# CFGAP register map
Vendor: Texas Instruments
Peripheral module from a debugger description file (folder AP).
Registers are 32-bit, read-only, reset 0x0 unless marked. A register's access mark holds for its fields unless they carry their own. Offsets are as the file gives them; lines under a group give offsets from that group; [hi:lo] are bit positions; {n}, {i} and the like mark numbered series; 'fields as' and 'values as' point back to an identical list; <NAME> marks a mode.

## Hidden
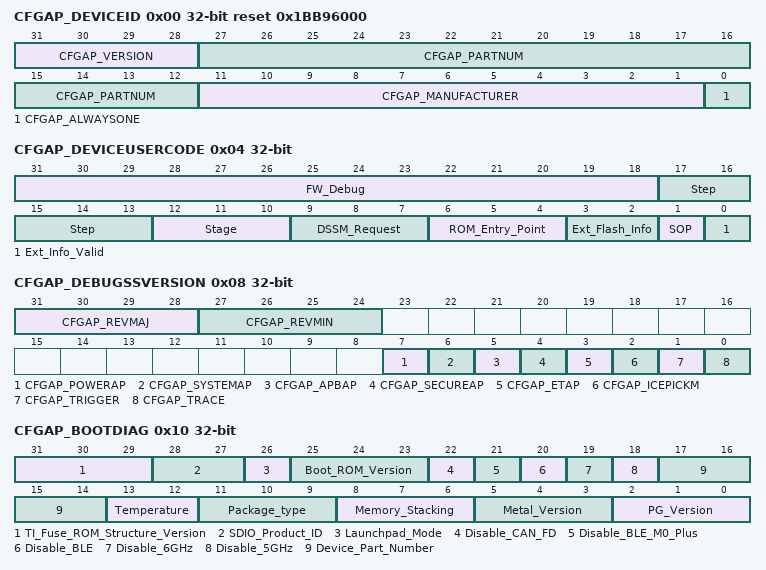
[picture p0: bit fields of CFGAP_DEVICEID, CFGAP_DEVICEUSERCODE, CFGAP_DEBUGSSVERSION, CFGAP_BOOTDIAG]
0x00 CFGAP_DEVICEID reset 0x1BB96000
  [31:28] CFGAP_VERSION, [27:12] CFGAP_PARTNUM, [11:1] CFGAP_MANUFACTURER, [0] CFGAP_ALWAYSONE
0x04 CFGAP_DEVICEUSERCODE
  [31:18] FW_Debug, [17:13] Step, [12:10] Stage, [9:7] DSSM_Request, [6:4] ROM_Entry_Point, [3:2] Ext_Flash_Info, [1] SOP, [0] Ext_Info_Valid
0x08 CFGAP_DEBUGSSVERSION
  [31:28] CFGAP_REVMAJ, [27:24] CFGAP_REVMIN, [7] CFGAP_POWERAP, [6] CFGAP_SYSTEMAP, [5] CFGAP_APBAP, [4] CFGAP_SECUREAP, [3] CFGAP_ETAP, [2] CFGAP_ICEPICKM, [1] CFGAP_TRIGGER, [0] CFGAP_TRACE
0x0C CFGAP_SYSSTATCTRL access not given reset not defined
0x10 CFGAP_BOOTDIAG
  [31:29] TI_Fuse_ROM_Structure_Version, [28:27] SDIO_Product_ID, [26] Launchpad_Mode, [25:23] Boot_ROM_Version, [22] Disable_CAN_FD, [21] Disable_BLE_M0_Plus, [20] Disable_BLE, [19] Disable_6GHz, [18] Disable_5GHz, [17:14] Device_Part_Number, [13:12] Temperature, [11:9] Package_type, [8:6] Memory_Stacking, [5:3] Metal_Version, [2:0] PG_Version
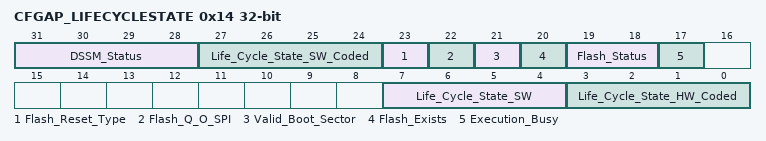
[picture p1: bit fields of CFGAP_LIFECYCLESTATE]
0x14 CFGAP_LIFECYCLESTATE
  [31:28] DSSM_Status, [27:24] Life_Cycle_State_SW_Coded, [23] Flash_Reset_Type, [22] Flash_Q_O_SPI, [21] Valid_Boot_Sector, [20] Flash_Exists, [19:18] Flash_Status, [17] Execution_Busy, [7:4] Life_Cycle_State_SW, [3:0] Life_Cycle_State_HW_Coded
0x18 DFT_EN access per field
  [0] MEM_DFT_EN rw
0x1C RESET_REQ access per field
  [0] Reset_Req rw
0x28 CFGAP_UNIQUE_DEVICEID0
  [31:0] CFGAP_UNIQUE_DEVICEID_VALUE_LOW
0x2C CFGAP_UNIQUE_DEVICEID1
  [31:0] CFGAP_UNIQUE_DEVICEID_VALUE_HIGH
